AUTOSAR XML (schema 314)
package /ComponentType
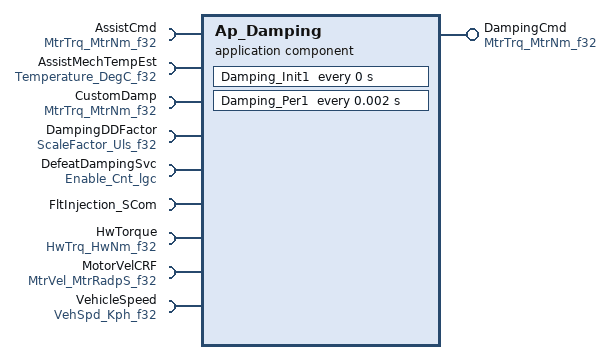
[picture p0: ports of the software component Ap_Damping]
  application software component type Ap_Damping
    provide port DampingCmd: unqueued-sender-com-spec{data-element=MtrNm_f32, can-invalidate=false, init-value=D_ZERO_ULS_F32}, provided-interface=MtrTrq_MtrNm_f32
    9 x require port:
      AssistCmd: unqueued-receiver-com-spec{data-element=MtrNm_f32, init-value=D_ZERO_ULS_F32}, required-interface=MtrTrq_MtrNm_f32
      AssistMechTempEst: unqueued-receiver-com-spec{data-element=DegC_f32, init-value=D_ZERO_ULS_F32}, required-interface=Temperature_DegC_f32
      CustomDamp: unqueued-receiver-com-spec{data-element=MtrNm_f32, init-value=D_ZERO_ULS_F32}, required-interface=MtrTrq_MtrNm_f32
      DampingDDFactor: unqueued-receiver-com-spec{data-element=Uls_f32, init-value=D_ONE_ULS_F32}, required-interface=ScaleFactor_Uls_f32
      DefeatDampingSvc: unqueued-receiver-com-spec{data-element=Cnt_lgc, init-value=D_FALSE_CNT_LGC}, required-interface=Enable_Cnt_lgc
      FltInjection_SCom: client-com-spec=FltInjection, required-interface=FltInjection_SCom
      HwTorque: unqueued-receiver-com-spec{data-element=HwNm_f32, init-value=D_ZERO_ULS_F32}, required-interface=HwTrq_HwNm_f32
      MotorVelCRF: unqueued-receiver-com-spec{data-element=MtrRadpS_f32, init-value=D_ZERO_ULS_F32}, required-interface=MtrVel_MtrRadpS_f32
      VehicleSpeed: unqueued-receiver-com-spec{data-element=Kph_f32, init-value=D_ZERO_ULS_F32}, required-interface=VehSpd_Kph_f32
  internal behavior Ap_Damping_InternalBehavior: component=Ap_Damping
    timing event Damping_Init1_InitEvent: start-on-event=Damping_Init1, period=0
    timing event TMT_Damping_Per1: start-on-event=Damping_Per1, period=0.002
    port-api-options:
      enable-take-address=false, indirect-api=false, port=AssistCmd
      enable-take-address=false, indirect-api=false, port=AssistMechTempEst
      enable-take-address=false, indirect-api=false, port=CustomDamp
      enable-take-address=false, indirect-api=false, port=DampingCmd
      enable-take-address=false, indirect-api=false, port=DampingDDFactor
      enable-take-address=false, indirect-api=false, port=DefeatDampingSvc
      enable-take-address=false, indirect-api=false, port=FltInjection_SCom
      enable-take-address=false, indirect-api=false, port=HwTorque
      enable-take-address=false, indirect-api=false, port=MotorVelCRF
      enable-take-address=false, indirect-api=false, port=VehicleSpeed
    runnable Damping_Init1
    runnable Damping_Per1
      8 x data read access:
        READ_AssistCmd_MtrNm_f32: data-element=AssistCmd.MtrNm_f32
        READ_AssistMechTempEst_DegC_f32: data-element=AssistMechTempEst.DegC_f32
        READ_CustomDamp_MtrNm_f32: data-element=CustomDamp.MtrNm_f32
        READ_DampingDDFactor_Uls_f32: data-element=DampingDDFactor.Uls_f32
        READ_DefeatDampingSvc_Cnt_lgc: data-element=DefeatDampingSvc.Cnt_lgc
        READ_HwTorque_HwNm_f32: data-element=HwTorque.HwNm_f32
        READ_MotorVelCRF_MtrRadpS_f32: data-element=MotorVelCRF.MtrRadpS_f32
        READ_VehicleSpeed_Kph_f32: data-element=VehicleSpeed.Kph_f32
      data write access WRITE_DampingCmd_MtrNm_f32: data-element=DampingCmd.MtrNm_f32
      sync call SC_FltInjection_SCom_FltInjection: operation=FltInjection_SCom.FltInjection, timeout=0
  swc implementation Ap_Damping_Implementation: behavior=Ap_Damping_InternalBehavior
    code-descriptors:
      code Code: type=SRC
